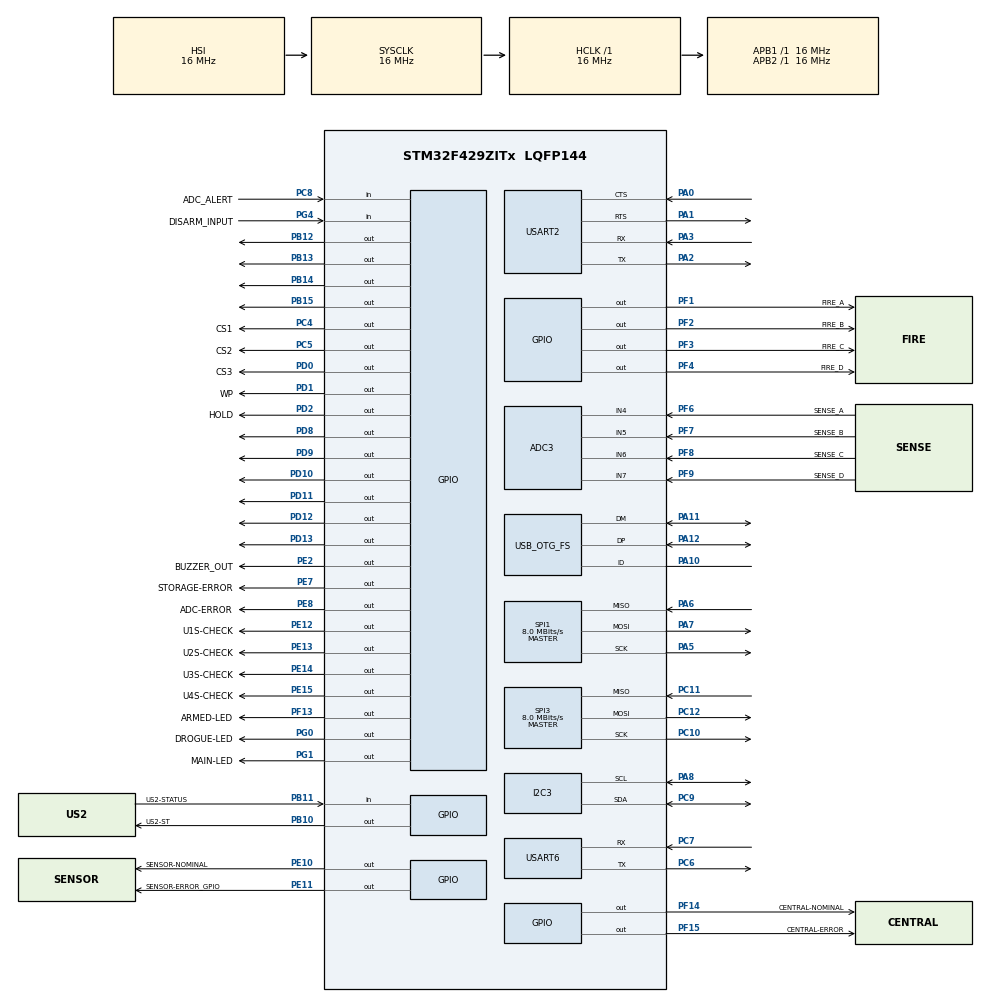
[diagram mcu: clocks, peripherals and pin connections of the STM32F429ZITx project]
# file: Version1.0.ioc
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ADC3.Channel-0\#ChannelRegularConversion=ADC_CHANNEL_4
ADC3.NbrOfConversionFlag=1
ADC3.Rank-0\#ChannelRegularConversion=1
ADC3.SamplingTime-0\#ChannelRegularConversion=ADC_SAMPLETIME_3CYCLES
FREERTOS.Tasks01=defaultTask,0,128,StartDefaultTask,Default,NULL,Dynamic,NULL,NULL;Acquisition,3,128,setupAcquisition,Default,NULL,Static,AcquisitionBuffer,AcquisitionControlBlock;Processing,0,128,startProcessing,Default,NULL,Static,ProcessingBuffer,ProcessingControlBlock;ControlLogic,0,128,startControlLogic,Default,hotBoot,Static,ControlLogicBuffer,ControlLogicControlBlock;Montoring,-2,128,startMonitoring,Default,hotBoot,Static,MontoringBuffer,MontoringControlBlock;Storage,2,128,setupStorage,Default,NULL,Static,StorageBuffer,StorageControlBlock;Transmission,2,128,setupTransmission,Default,NULL,Static,TransmissionBuffer,TransmissionControlBlock
Mcu.Family=STM32F4
Mcu.Name=STM32F429ZITx
Mcu.Package=LQFP144
NVIC.PriorityGroup=NVIC_PRIORITYGROUP_4
NVIC.TIM1_UP_TIM10_IRQn=true\:0\:0\:false\:false\:true\:false\:false\:true
NVIC.TimeBase=TIM1_UP_TIM10_IRQn
NVIC.TimeBaseIP=TIM1
PA0/WKUP.Mode=CTS_RTS
PA0/WKUP.Signal=USART2_CTS
PA1.Mode=CTS_RTS
PA1.Signal=USART2_RTS
PA10.Mode=OTG/Dual_Role_Device
PA10.Signal=USB_OTG_FS_ID
PA11.Mode=OTG/Dual_Role_Device
PA11.Signal=USB_OTG_FS_DM
PA12.Mode=OTG/Dual_Role_Device
PA12.Signal=USB_OTG_FS_DP
PA13.Signal=SYS_JTMS-SWDIO
PA14.Signal=SYS_JTCK-SWCLK
PA2.Mode=Asynchronous
PA2.Signal=USART2_TX
PA3.Mode=Asynchronous
PA3.Signal=USART2_RX
PA5.Mode=Full_Duplex_Master
PA5.Signal=SPI1_SCK
PA6.Mode=Full_Duplex_Master
PA6.Signal=SPI1_MISO
PA7.Mode=Full_Duplex_Master
PA7.Signal=SPI1_MOSI
PA8.Mode=I2C
PA8.Signal=I2C3_SCL
PB10.GPIO_Label=US2-ST
PB10.Signal=GPIO_Output
PB11.GPIO_Label=US2-STATUS
PB11.Signal=GPIO_Input
PB12.Signal=GPIO_Output
PB13.Signal=GPIO_Output
PB14.Signal=GPIO_Output
PB15.Signal=GPIO_Output
PB3.Signal=SYS_JTDO-SWO
PC10.Mode=Full_Duplex_Master
PC10.Signal=SPI3_SCK
PC11.Mode=Full_Duplex_Master
PC11.Signal=SPI3_MISO
PC12.Mode=Full_Duplex_Master
PC12.Signal=SPI3_MOSI
PC4.GPIO_Label=CS1
PC4.Signal=GPIO_Output
PC5.GPIO_Label=CS2
PC5.Signal=GPIO_Output
PC6.Mode=Asynchronous
PC6.Signal=USART6_TX
PC7.Mode=Asynchronous
PC7.Signal=USART6_RX
PC8.GPIO_Label=ADC_ALERT
PC8.Signal=GPIO_Input
PC9.Mode=I2C
PC9.Signal=I2C3_SDA
PD0.GPIO_Label=CS3
PD0.Signal=GPIO_Output
PD1.GPIO_Label=WP
PD1.Signal=GPIO_Output
PD10.Signal=GPIO_Output
PD11.Signal=GPIO_Output
PD12.Signal=GPIO_Output
PD13.Signal=GPIO_Output
PD2.GPIO_Label=HOLD
PD2.Signal=GPIO_Output
PD8.Signal=GPIO_Output
PD9.Signal=GPIO_Output
PE10.GPIO_Label=SENSOR-NOMINAL
PE10.Signal=GPIO_Output
PE11.GPIO_Label=SENSOR-ERROR_GPIO
PE11.Signal=GPIO_Output
PE12.GPIO_Label=U1S-CHECK
PE12.Signal=GPIO_Output
PE13.GPIO_Label=U2S-CHECK
PE13.Signal=GPIO_Output
PE14.GPIO_Label=U3S-CHECK
PE14.Signal=GPIO_Output
PE15.GPIO_Label=U4S-CHECK
PE15.Signal=GPIO_Output
PE2.GPIO_Label=BUZZER_OUT
PE2.Signal=GPIO_Output
PE7.GPIO_Label=STORAGE-ERROR
PE7.Signal=GPIO_Output
PE8.GPIO_Label=ADC-ERROR
PE8.Signal=GPIO_Output
PF1.GPIO_Label=FIRE_A
PF1.Signal=GPIO_Output
PF13.GPIO_Label=ARMED-LED
PF13.Signal=GPIO_Output
PF14.GPIO_Label=CENTRAL-NOMINAL
PF14.Signal=GPIO_Output
PF15.GPIO_Label=CENTRAL-ERROR
PF15.Signal=GPIO_Output
PF2.GPIO_Label=FIRE_B
PF2.Signal=GPIO_Output
PF3.GPIO_Label=FIRE_C
PF3.Signal=GPIO_Output
PF4.GPIO_Label=FIRE_D
PF4.Signal=GPIO_Output
PF6.GPIO_Label=SENSE_A
PF6.Mode=IN4
PF6.Signal=ADC3_IN4
PF7.GPIO_Label=SENSE_B
PF7.Mode=IN5
PF7.Signal=ADC3_IN5
PF8.GPIO_Label=SENSE_C
PF8.Mode=IN6
PF8.Signal=ADC3_IN6
PF9.GPIO_Label=SENSE_D
PF9.Mode=IN7
PF9.Signal=ADC3_IN7
PG0.GPIO_Label=DROGUE-LED
PG0.Signal=GPIO_Output
PG1.GPIO_Label=MAIN-LED
PG1.Signal=GPIO_Output
PG4.GPIO_Label=DISARM_INPUT
PG4.Signal=GPIO_Input
PH0/OSC_IN.Mode=HSE-External-Oscillator
PH0/OSC_IN.Signal=RCC_OSC_IN
PH1/OSC_OUT.Mode=HSE-External-Oscillator
PH1/OSC_OUT.Signal=RCC_OSC_OUT
ProjectManager.HeapSize=0x200
ProjectManager.StackSize=0x400
ProjectManager.TargetToolchain=SW4STM32
RCC.48MHZClocksFreq_Value=48000000
RCC.AHBFreq_Value=16000000
RCC.APB1Freq_Value=16000000
RCC.APB2Freq_Value=16000000
RCC.CortexFreq_Value=16000000
RCC.HSE_VALUE=8000000
RCC.HSI_VALUE=16000000
RCC.LSE_VALUE=32768
RCC.PLLM=4
RCC.PLLN=72
RCC.PLLQ=3
RCC.SYSCLKFreq_VALUE=16000000
RCC.VCOOutputFreq_Value=144000000
SPI1.CalculateBaudRate=8.0 MBits/s
SPI1.Direction=SPI_DIRECTION_2LINES
SPI1.Mode=SPI_MODE_MASTER
SPI1.VirtualType=VM_MASTER
SPI3.CalculateBaudRate=8.0 MBits/s
SPI3.Direction=SPI_DIRECTION_2LINES
SPI3.Mode=SPI_MODE_MASTER
SPI3.VirtualType=VM_MASTER
USART2.VirtualMode=VM_ASYNC
USART6.VirtualMode=VM_ASYNC
USB_OTG_FS.VirtualMode=Host_Only
USB_OTG_FS.phy_itface=HCD_PHY_EMBEDDED
VP_FREERTOS_VS_CMSIS_V1.Mode=CMSIS_V1
VP_SYS_VS_tim1.Mode=TIM1
board=custom

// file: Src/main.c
/* USER CODE BEGIN Header */
/**
  ******************************************************************************
  * @file           : main.c
  * @brief          : Main program body
  ******************************************************************************
  * @attention
  *
  * <h2><center>&copy; Copyright (c) 2020 STMicroelectronics.
  * All rights reserved.</center></h2>
  *
  * This software component is licensed by ST under Ultimate Liberty license
  * SLA0044, the "License"; You may not use this file except in compliance with
  * the License. You may obtain a copy of the License at:
  *                             www.st.com/SLA0044
  *
  ******************************************************************************
  */
/* USER CODE END Header */

#include "main.h"
#include "cmsis_os.h"

/* USER CODE BEGIN Includes */

/* User-defined libraries */

#include "acquisition.h"
#include "controlLogic.h"
#include "monitoring.h"
#include "processing.h"
#include "storage.h"
#include "transmission.h"

/* C-libraries */

#include <stdbool.h>
#include <stdint.h>

/* USER CODE END Includes */

ADC_HandleTypeDef hadc3;

I2C_HandleTypeDef hi2c3;

SPI_HandleTypeDef hspi1;
SPI_HandleTypeDef hspi3;

UART_HandleTypeDef huart2;
UART_HandleTypeDef huart6;

osThreadId defaultTaskHandle;
osThreadId AcquisitionHandle;
uint32_t AcquisitionBuffer[ 128 ];
osStaticThreadDef_t AcquisitionControlBlock;
osThreadId ProcessingHandle;
uint32_t ProcessingBuffer[ 128 ];
osStaticThreadDef_t ProcessingControlBlock;
osThreadId ControlLogicHandle;
uint32_t ControlLogicBuffer[ 128 ];
osStaticThreadDef_t ControlLogicControlBlock;
osThreadId MontoringHandle;
uint32_t MontoringBuffer[ 128 ];
osStaticThreadDef_t MontoringControlBlock;
osThreadId StorageHandle;
uint32_t StorageBuffer[ 128 ];
osStaticThreadDef_t StorageControlBlock;
osThreadId TransmissionHandle;
uint32_t TransmissionBuffer[ 128 ];
osStaticThreadDef_t TransmissionControlBlock;

void SystemClock_Config(void);
static void MX_GPIO_Init(void);
static void MX_ADC3_Init(void);
static void MX_I2C3_Init(void);
static void MX_SPI1_Init(void);
static void MX_SPI3_Init(void);
static void MX_USART2_UART_Init(void);
static void MX_USART6_UART_Init(void);
static void MX_USB_OTG_FS_USB_Init(void);
void StartDefaultTask(void const * argument);
void setupAcquisition(void const * argument);
void startProcessing(void const * argument);
void startControlLogic(void const * argument);
void startMonitoring(void const * argument);
void setupStorage(void const * argument);
void setupTransmission(void const * argument);

int main(void)
{

  /* MCU Configuration--------------------------------------------------------*/

  /* Reset of all peripherals, Initializes the Flash interface and the Systick. */
  HAL_Init();

  /* Configure the system clock */
  SystemClock_Config();

  /* Initialize all configured peripherals */
  MX_GPIO_Init();
  MX_ADC3_Init();
  MX_I2C3_Init();
  MX_SPI1_Init();
  MX_SPI3_Init();
  MX_USART2_UART_Init();
  MX_USART6_UART_Init();
  MX_USB_OTG_FS_USB_Init();

  /* Create the thread(s) */
  /* definition and creation of defaultTask */
  osThreadDef(defaultTask, StartDefaultTask, osPriorityNormal, 0, 128);
  defaultTaskHandle = osThreadCreate(osThread(defaultTask), NULL);

  /* definition and creation of Acquisition */
  osThreadStaticDef(Acquisition, setupAcquisition, osPriorityRealtime, 0, 128, AcquisitionBuffer, &AcquisitionControlBlock);
  AcquisitionHandle = osThreadCreate(osThread(Acquisition), NULL);

  /* definition and creation of Processing */
  osThreadStaticDef(Processing, startProcessing, osPriorityNormal, 0, 128, ProcessingBuffer, &ProcessingControlBlock);
  ProcessingHandle = osThreadCreate(osThread(Processing), NULL);

  /* definition and creation of ControlLogic */
  osThreadStaticDef(ControlLogic, startControlLogic, osPriorityNormal, 0, 128, ControlLogicBuffer, &ControlLogicControlBlock);
  ControlLogicHandle = osThreadCreate(osThread(ControlLogic), (void*) hotBoot);

  /* definition and creation of Montoring */
  osThreadStaticDef(Montoring, startMonitoring, osPriorityLow, 0, 128, MontoringBuffer, &MontoringControlBlock);
  MontoringHandle = osThreadCreate(osThread(Montoring), (void*) hotBoot);

  /* definition and creation of Storage */
  osThreadStaticDef(Storage, setupStorage, osPriorityHigh, 0, 128, StorageBuffer, &StorageControlBlock);
  StorageHandle = osThreadCreate(osThread(Storage), NULL);

  /* definition and creation of Transmission */
  osThreadStaticDef(Transmission, setupTransmission, osPriorityHigh, 0, 128, TransmissionBuffer, &TransmissionControlBlock);
  TransmissionHandle = osThreadCreate(osThread(Transmission), NULL);

  /* Start scheduler */
  osKernelStart();

  /* We should never get here as control is now taken by the scheduler */

  /* Infinite loop */
  while (1)
  {

  }
}

void SystemClock_Config(void)
{
  RCC_OscInitTypeDef RCC_OscInitStruct = {0};
  RCC_ClkInitTypeDef RCC_ClkInitStruct = {0};

  /** Configure the main internal regulator output voltage
  */
  __HAL_RCC_PWR_CLK_ENABLE();
  __HAL_PWR_VOLTAGESCALING_CONFIG(PWR_REGULATOR_VOLTAGE_SCALE3);
  /** Initializes the CPU, AHB and APB busses clocks
  */
  RCC_OscInitStruct.OscillatorType = RCC_OSCILLATORTYPE_HSI|RCC_OSCILLATORTYPE_HSE;
  RCC_OscInitStruct.HSEState = RCC_HSE_ON;
  RCC_OscInitStruct.HSIState = RCC_HSI_ON;
  RCC_OscInitStruct.HSICalibrationValue = RCC_HSICALIBRATION_DEFAULT;
  RCC_OscInitStruct.PLL.PLLState = RCC_PLL_ON;
  RCC_OscInitStruct.PLL.PLLSource = RCC_PLLSOURCE_HSE;
  RCC_OscInitStruct.PLL.PLLM = 4;
  RCC_OscInitStruct.PLL.PLLN = 72;
  RCC_OscInitStruct.PLL.PLLP = RCC_PLLP_DIV2;
  RCC_OscInitStruct.PLL.PLLQ = 3;
  if (HAL_RCC_OscConfig(&RCC_OscInitStruct) != HAL_OK)
  {
    Error_Handler();
  }
  /** Initializes the CPU, AHB and APB busses clocks
  */
  RCC_ClkInitStruct.ClockType = RCC_CLOCKTYPE_HCLK|RCC_CLOCKTYPE_SYSCLK
                              |RCC_CLOCKTYPE_PCLK1|RCC_CLOCKTYPE_PCLK2;
  RCC_ClkInitStruct.SYSCLKSource = RCC_SYSCLKSOURCE_HSI;
  RCC_ClkInitStruct.AHBCLKDivider = RCC_SYSCLK_DIV1;
  RCC_ClkInitStruct.APB1CLKDivider = RCC_HCLK_DIV1;
  RCC_ClkInitStruct.APB2CLKDivider = RCC_HCLK_DIV1;

  if (HAL_RCC_ClockConfig(&RCC_ClkInitStruct, FLASH_LATENCY_0) != HAL_OK)
  {
    Error_Handler();
  }
}

static void MX_ADC3_Init(void)
{

  ADC_ChannelConfTypeDef sConfig = {0};

  /** Configure the global features of the ADC (Clock, Resolution, Data Alignment and number of conversion)
  */
  hadc3.Instance = ADC3;
  hadc3.Init.ClockPrescaler = ADC_CLOCK_SYNC_PCLK_DIV2;
  hadc3.Init.Resolution = ADC_RESOLUTION_12B;
  hadc3.Init.ScanConvMode = DISABLE;
  hadc3.Init.ContinuousConvMode = DISABLE;
  hadc3.Init.DiscontinuousConvMode = DISABLE;
  hadc3.Init.ExternalTrigConvEdge = ADC_EXTERNALTRIGCONVEDGE_NONE;
  hadc3.Init.ExternalTrigConv = ADC_SOFTWARE_START;
  hadc3.Init.DataAlign = ADC_DATAALIGN_RIGHT;
  hadc3.Init.NbrOfConversion = 1;
  hadc3.Init.DMAContinuousRequests = DISABLE;
  hadc3.Init.EOCSelection = ADC_EOC_SINGLE_CONV;
  if (HAL_ADC_Init(&hadc3) != HAL_OK)
  {
    Error_Handler();
  }
  /** Configure for the selected ADC regular channel its corresponding rank in the sequencer and its sample time.
  */
  sConfig.Channel = ADC_CHANNEL_4;
  sConfig.Rank = 1;
  sConfig.SamplingTime = ADC_SAMPLETIME_3CYCLES;
  if (HAL_ADC_ConfigChannel(&hadc3, &sConfig) != HAL_OK)
  {
    Error_Handler();
  }

}

static void MX_I2C3_Init(void)
{

  hi2c3.Instance = I2C3;
  hi2c3.Init.ClockSpeed = 100000;
  hi2c3.Init.DutyCycle = I2C_DUTYCYCLE_2;
  hi2c3.Init.OwnAddress1 = 0;
  hi2c3.Init.AddressingMode = I2C_ADDRESSINGMODE_7BIT;
  hi2c3.Init.DualAddressMode = I2C_DUALADDRESS_DISABLE;
  hi2c3.Init.OwnAddress2 = 0;
  hi2c3.Init.GeneralCallMode = I2C_GENERALCALL_DISABLE;
  hi2c3.Init.NoStretchMode = I2C_NOSTRETCH_DISABLE;
  if (HAL_I2C_Init(&hi2c3) != HAL_OK)
  {
    Error_Handler();
  }
  /** Configure Analogue filter
  */
  if (HAL_I2CEx_ConfigAnalogFilter(&hi2c3, I2C_ANALOGFILTER_ENABLE) != HAL_OK)
  {
    Error_Handler();
  }
  /** Configure Digital filter
  */
  if (HAL_I2CEx_ConfigDigitalFilter(&hi2c3, 0) != HAL_OK)
  {
    Error_Handler();
  }

}

static void MX_SPI1_Init(void)
{

  /* SPI1 parameter configuration*/
  hspi1.Instance = SPI1;
  hspi1.Init.Mode = SPI_MODE_MASTER;
  hspi1.Init.Direction = SPI_DIRECTION_2LINES;
  hspi1.Init.DataSize = SPI_DATASIZE_8BIT;
  hspi1.Init.CLKPolarity = SPI_POLARITY_LOW;
  hspi1.Init.CLKPhase = SPI_PHASE_1EDGE;
  hspi1.Init.NSS = SPI_NSS_SOFT;
  hspi1.Init.BaudRatePrescaler = SPI_BAUDRATEPRESCALER_2;
  hspi1.Init.FirstBit = SPI_FIRSTBIT_MSB;
  hspi1.Init.TIMode = SPI_TIMODE_DISABLE;
  hspi1.Init.CRCCalculation = SPI_CRCCALCULATION_DISABLE;
  hspi1.Init.CRCPolynomial = 10;
  if (HAL_SPI_Init(&hspi1) != HAL_OK)
  {
    Error_Handler();
  }

}

static void MX_SPI3_Init(void)
{

  /* SPI3 parameter configuration*/
  hspi3.Instance = SPI3;
  hspi3.Init.Mode = SPI_MODE_MASTER;
  hspi3.Init.Direction = SPI_DIRECTION_2LINES;
  hspi3.Init.DataSize = SPI_DATASIZE_8BIT;
  hspi3.Init.CLKPolarity = SPI_POLARITY_LOW;
  hspi3.Init.CLKPhase = SPI_PHASE_1EDGE;
  hspi3.Init.NSS = SPI_NSS_SOFT;
  hspi3.Init.BaudRatePrescaler = SPI_BAUDRATEPRESCALER_2;
  hspi3.Init.FirstBit = SPI_FIRSTBIT_MSB;
  hspi3.Init.TIMode = SPI_TIMODE_DISABLE;
  hspi3.Init.CRCCalculation = SPI_CRCCALCULATION_DISABLE;
  hspi3.Init.CRCPolynomial = 10;
  if (HAL_SPI_Init(&hspi3) != HAL_OK)
  {
    Error_Handler();
  }

}

static void MX_USART2_UART_Init(void)
{

  huart2.Instance = USART2;
  huart2.Init.BaudRate = 115200;
  huart2.Init.WordLength = UART_WORDLENGTH_8B;
  huart2.Init.StopBits = UART_STOPBITS_1;
  huart2.Init.Parity = UART_PARITY_NONE;
  huart2.Init.Mode = UART_MODE_TX_RX;
  huart2.Init.HwFlowCtl = UART_HWCONTROL_RTS_CTS;
  huart2.Init.OverSampling = UART_OVERSAMPLING_16;
  if (HAL_UART_Init(&huart2) != HAL_OK)
  {
    Error_Handler();
  }

}

static void MX_USART6_UART_Init(void)
{

  huart6.Instance = USART6;
  huart6.Init.BaudRate = 115200;
  huart6.Init.WordLength = UART_WORDLENGTH_8B;
  huart6.Init.StopBits = UART_STOPBITS_1;
  huart6.Init.Parity = UART_PARITY_NONE;
  huart6.Init.Mode = UART_MODE_TX_RX;
  huart6.Init.HwFlowCtl = UART_HWCONTROL_NONE;
  huart6.Init.OverSampling = UART_OVERSAMPLING_16;
  if (HAL_UART_Init(&huart6) != HAL_OK)
  {
    Error_Handler();
  }

}

static void MX_USB_OTG_FS_USB_Init(void)
{

}

static void MX_GPIO_Init(void)
{
  GPIO_InitTypeDef GPIO_InitStruct = {0};

  /* GPIO Ports Clock Enable */
  __HAL_RCC_GPIOE_CLK_ENABLE();
  __HAL_RCC_GPIOF_CLK_ENABLE();
  __HAL_RCC_GPIOH_CLK_ENABLE();
  __HAL_RCC_GPIOA_CLK_ENABLE();
  __HAL_RCC_GPIOC_CLK_ENABLE();
  __HAL_RCC_GPIOG_CLK_ENABLE();
  __HAL_RCC_GPIOB_CLK_ENABLE();
  __HAL_RCC_GPIOD_CLK_ENABLE();

  /*Configure GPIO pin Output Level */
  HAL_GPIO_WritePin(GPIOE, BUZZER_OUT_Pin|STORAGE_ERROR_Pin|ADC_ERROR_Pin|SENSOR_NOMINAL_Pin
                          |SENSOR_ERROR_GPIO_Pin|U1S_CHECK_Pin|U2S_CHECK_Pin|U3S_CHECK_Pin
                          |U4S_CHECK_Pin, GPIO_PIN_RESET);

  /*Configure GPIO pin Output Level */
  HAL_GPIO_WritePin(GPIOF, FIRE_A_Pin|FIRE_B_Pin|FIRE_C_Pin|FIRE_D_Pin
                          |ARMED_LED_Pin|CENTRAL_NOMINAL_Pin|CENTRAL_ERROR_Pin, GPIO_PIN_RESET);

  /*Configure GPIO pin Output Level */
  HAL_GPIO_WritePin(GPIOC, CS1_Pin|CS2_Pin, GPIO_PIN_RESET);

  /*Configure GPIO pin Output Level */
  HAL_GPIO_WritePin(GPIOG, DROGUE_LED_Pin|MAIN_LED_Pin, GPIO_PIN_RESET);

  /*Configure GPIO pin Output Level */
  HAL_GPIO_WritePin(GPIOB, US2_ST_Pin|GPIO_PIN_12|GPIO_PIN_13|GPIO_PIN_14
                          |GPIO_PIN_15, GPIO_PIN_RESET);

  /*Configure GPIO pin Output Level */
  HAL_GPIO_WritePin(GPIOD, GPIO_PIN_8|GPIO_PIN_9|GPIO_PIN_10|GPIO_PIN_11
                          |GPIO_PIN_12|GPIO_PIN_13|CS3_Pin|WP_Pin
                          |HOLD_Pin, GPIO_PIN_RESET);

  /*Configure GPIO pins : BUZZER_OUT_Pin STORAGE_ERROR_Pin ADC_ERROR_Pin SENSOR_NOMINAL_Pin
                           SENSOR_ERROR_GPIO_Pin U1S_CHECK_Pin U2S_CHECK_Pin U3S_CHECK_Pin
                           U4S_CHECK_Pin */
  GPIO_InitStruct.Pin = BUZZER_OUT_Pin|STORAGE_ERROR_Pin|ADC_ERROR_Pin|SENSOR_NOMINAL_Pin
                          |SENSOR_ERROR_GPIO_Pin|U1S_CHECK_Pin|U2S_CHECK_Pin|U3S_CHECK_Pin
                          |U4S_CHECK_Pin;
  GPIO_InitStruct.Mode = GPIO_MODE_OUTPUT_PP;
  GPIO_InitStruct.Pull = GPIO_NOPULL;
  GPIO_InitStruct.Speed = GPIO_SPEED_FREQ_LOW;
  HAL_GPIO_Init(GPIOE, &GPIO_InitStruct);

  /*Configure GPIO pins : FIRE_A_Pin FIRE_B_Pin FIRE_C_Pin FIRE_D_Pin
                           ARMED_LED_Pin CENTRAL_NOMINAL_Pin CENTRAL_ERROR_Pin */
  GPIO_InitStruct.Pin = FIRE_A_Pin|FIRE_B_Pin|FIRE_C_Pin|FIRE_D_Pin
                          |ARMED_LED_Pin|CENTRAL_NOMINAL_Pin|CENTRAL_ERROR_Pin;
  GPIO_InitStruct.Mode = GPIO_MODE_OUTPUT_PP;
  GPIO_InitStruct.Pull = GPIO_NOPULL;
  GPIO_InitStruct.Speed = GPIO_SPEED_FREQ_LOW;
  HAL_GPIO_Init(GPIOF, &GPIO_InitStruct);

  /*Configure GPIO pins : CS1_Pin CS2_Pin */
  GPIO_InitStruct.Pin = CS1_Pin|CS2_Pin;
  GPIO_InitStruct.Mode = GPIO_MODE_OUTPUT_PP;
  GPIO_InitStruct.Pull = GPIO_NOPULL;
  GPIO_InitStruct.Speed = GPIO_SPEED_FREQ_LOW;
  HAL_GPIO_Init(GPIOC, &GPIO_InitStruct);

  /*Configure GPIO pins : DROGUE_LED_Pin MAIN_LED_Pin */
  GPIO_InitStruct.Pin = DROGUE_LED_Pin|MAIN_LED_Pin;
  GPIO_InitStruct.Mode = GPIO_MODE_OUTPUT_PP;
  GPIO_InitStruct.Pull = GPIO_NOPULL;
  GPIO_InitStruct.Speed = GPIO_SPEED_FREQ_LOW;
  HAL_GPIO_Init(GPIOG, &GPIO_InitStruct);

  /*Configure GPIO pins : US2_ST_Pin PB12 PB13 PB14
                           PB15 */
  GPIO_InitStruct.Pin = US2_ST_Pin|GPIO_PIN_12|GPIO_PIN_13|GPIO_PIN_14
                          |GPIO_PIN_15;
  GPIO_InitStruct.Mode = GPIO_MODE_OUTPUT_PP;
  GPIO_InitStruct.Pull = GPIO_NOPULL;
  GPIO_InitStruct.Speed = GPIO_SPEED_FREQ_LOW;
  HAL_GPIO_Init(GPIOB, &GPIO_InitStruct);

  /*Configure GPIO pin : US2_STATUS_Pin */
  GPIO_InitStruct.Pin = US2_STATUS_Pin;
  GPIO_InitStruct.Mode = GPIO_MODE_INPUT;
  GPIO_InitStruct.Pull = GPIO_NOPULL;
  HAL_GPIO_Init(US2_STATUS_GPIO_Port, &GPIO_InitStruct);

  /*Configure GPIO pins : PD8 PD9 PD10 PD11
                           PD12 PD13 CS3_Pin WP_Pin
                           HOLD_Pin */
  GPIO_InitStruct.Pin = GPIO_PIN_8|GPIO_PIN_9|GPIO_PIN_10|GPIO_PIN_11
                          |GPIO_PIN_12|GPIO_PIN_13|CS3_Pin|WP_Pin
                          |HOLD_Pin;
  GPIO_InitStruct.Mode = GPIO_MODE_OUTPUT_PP;
  GPIO_InitStruct.Pull = GPIO_NOPULL;
  GPIO_InitStruct.Speed = GPIO_SPEED_FREQ_LOW;
  HAL_GPIO_Init(GPIOD, &GPIO_InitStruct);

  /*Configure GPIO pin : DISARM_INPUT_Pin */
  GPIO_InitStruct.Pin = DISARM_INPUT_Pin;
  GPIO_InitStruct.Mode = GPIO_MODE_INPUT;
  GPIO_InitStruct.Pull = GPIO_NOPULL;
  HAL_GPIO_Init(DISARM_INPUT_GPIO_Port, &GPIO_InitStruct);

  /*Configure GPIO pin : ADC_ALERT_Pin */
  GPIO_InitStruct.Pin = ADC_ALERT_Pin;
  GPIO_InitStruct.Mode = GPIO_MODE_INPUT;
  GPIO_InitStruct.Pull = GPIO_NOPULL;
  HAL_GPIO_Init(ADC_ALERT_GPIO_Port, &GPIO_InitStruct);

  /*Configure GPIO pins : PA10 PA11 PA12 */
  GPIO_InitStruct.Pin = GPIO_PIN_10|GPIO_PIN_11|GPIO_PIN_12;
  GPIO_InitStruct.Mode = GPIO_MODE_AF_PP;
  GPIO_InitStruct.Pull = GPIO_NOPULL;
  GPIO_InitStruct.Speed = GPIO_SPEED_FREQ_VERY_HIGH;
  GPIO_InitStruct.Alternate = GPIO_AF10_OTG_FS;
  HAL_GPIO_Init(GPIOA, &GPIO_InitStruct);

}

void StartDefaultTask(void const * argument)
{
  for(;;)
  {
    osDelay(1);
  }
}

void setupAcquisition(void const * argument)
{
  for(;;)
  {
    osDelay(1);
  }
}

void startProcessing(void const * argument)
{
  for(;;)
  {
    osDelay(1);
  }
}

void startControlLogic(void const * argument)
{
  for(;;)
  {
    osDelay(1);
  }
}

void startMonitoring(void const * argument)
{
  for(;;)
  {
    osDelay(1);
  }
}

void setupStorage(void const * argument)
{
  for(;;)
  {
    osDelay(1);
  }
}

void setupTransmission(void const * argument)
{
  for(;;)
  {
    osDelay(1);
  }
}

void HAL_TIM_PeriodElapsedCallback(TIM_HandleTypeDef *htim)
{
  if (htim->Instance == TIM1) {
    HAL_IncTick();
  }
}

void Error_Handler(void)
{
}

/************************ (C) COPYRIGHT STMicroelectronics *****END OF FILE****/
